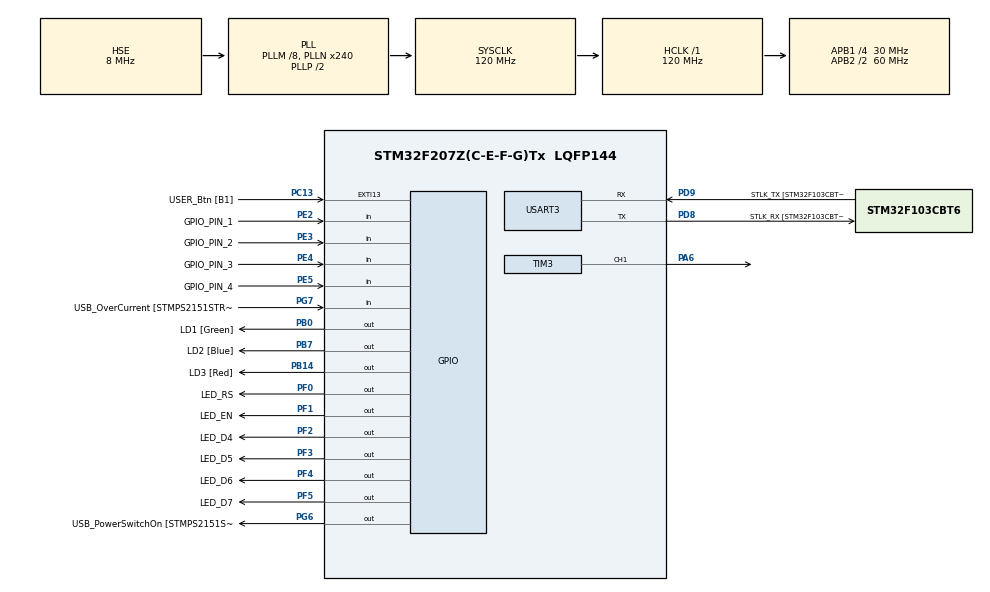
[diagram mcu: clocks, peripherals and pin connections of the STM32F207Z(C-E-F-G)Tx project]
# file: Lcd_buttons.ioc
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Mcu.Family=STM32F2
Mcu.Name=STM32F207Z(C-E-F-G)Tx
Mcu.Package=LQFP144
NVIC.PriorityGroup=NVIC_PRIORITYGROUP_4
NVIC.TIM3_IRQn=true\:0\:0\:false\:false\:true\:true\:true\:true
NVIC.TIM6_DAC_IRQn=true\:0\:0\:false\:false\:true\:true\:true\:true
PA1.GPIO_Label=RMII_REF_CLK [LAN8742A-CZ-TR_REFCLK0]
PA1.Signal=ETH_REF_CLK
PA10.GPIO_Label=USB_ID
PA10.Signal=USB_OTG_FS_ID
PA11.GPIO_Label=USB_DM
PA11.Signal=USB_OTG_FS_DM
PA12.GPIO_Label=USB_DP
PA12.Signal=USB_OTG_FS_DP
PA13.GPIO_Label=TMS
PA13.Mode=Serial_Wire
PA13.Signal=SYS_JTMS-SWDIO
PA14.GPIO_Label=TCK
PA14.Mode=Serial_Wire
PA14.Signal=SYS_JTCK-SWCLK
PA2.GPIO_Label=RMII_MDIO [LAN8742A-CZ-TR_MDIO]
PA2.Signal=ETH_MDIO
PA6.Signal=S_TIM3_CH1
PA7.GPIO_Label=RMII_CRS_DV [LAN8742A-CZ-TR_CRS_DV]
PA7.Signal=ETH_CRS_DV
PA8.GPIO_Label=USB_SOF [TP1]
PA8.Signal=USB_OTG_FS_SOF
PA9.GPIO_Label=USB_VBUS
PA9.Signal=USB_OTG_FS_VBUS
PB0.GPIO_Label=LD1 [Green]
PB0.Signal=GPIO_Output
PB13.GPIO_Label=RMII_TXD1 [LAN8742A-CZ-TR_TXD1]
PB13.Signal=ETH_TXD1
PB14.GPIO_Label=LD3 [Red]
PB14.Signal=GPIO_Output
PB3.GPIO_Label=SWO
PB3.Signal=SYS_JTDO-SWO
PB7.GPIO_Label=LD2 [Blue]
PB7.Signal=GPIO_Output
PC1.GPIO_Label=RMII_MDC [LAN8742A-CZ-TR_MDC]
PC1.Signal=ETH_MDC
PC13.GPIO_Label=USER_Btn [B1]
PC13.Signal=GPXTI13
PC14-OSC32_IN.Mode=LSE-External-Oscillator
PC14-OSC32_IN.Signal=RCC_OSC32_IN
PC15-OSC32_OUT.Mode=LSE-External-Oscillator
PC15-OSC32_OUT.Signal=RCC_OSC32_OUT
PC4.GPIO_Label=RMII_RXD0 [LAN8742A-CZ-TR_RXD0]
PC4.Signal=ETH_RXD0
PC5.GPIO_Label=RMII_RXD1 [LAN8742A-CZ-TR_RXD1]
PC5.Signal=ETH_RXD1
PD8.GPIO_Label=STLK_RX [STM32F103CBT6_PA2]
PD8.Mode=Asynchronous
PD8.Signal=USART3_TX
PD9.GPIO_Label=STLK_TX [STM32F103CBT6_PA3]
PD9.Mode=Asynchronous
PD9.Signal=USART3_RX
PE2.GPIO_Label=GPIO_PIN_1
PE2.GPIO_PuPd=GPIO_PULLDOWN
PE2.Signal=GPIO_Input
PE3.GPIO_Label=GPIO_PIN_2
PE3.GPIO_PuPd=GPIO_PULLDOWN
PE3.Signal=GPIO_Input
PE4.GPIO_Label=GPIO_PIN_3
PE4.GPIO_PuPd=GPIO_PULLDOWN
PE4.Signal=GPIO_Input
PE5.GPIO_Label=GPIO_PIN_4
PE5.GPIO_PuPd=GPIO_PULLDOWN
PE5.Signal=GPIO_Input
PF0.GPIO_Label=LED_RS
PF0.Signal=GPIO_Output
PF1.GPIO_Label=LED_EN
PF1.Signal=GPIO_Output
PF2.GPIO_Label=LED_D4
PF2.Signal=GPIO_Output
PF3.GPIO_Label=LED_D5
PF3.Signal=GPIO_Output
PF4.GPIO_Label=LED_D6
PF4.Signal=GPIO_Output
PF5.GPIO_Label=LED_D7
PF5.Signal=GPIO_Output
PG11.GPIO_Label=RMII_TX_EN [LAN8742A-CZ-TR_TXEN]
PG11.Signal=ETH_TX_EN
PG13.GPIO_Label=RMII_TXD0 [LAN8742A-CZ-TR_TXD0]
PG13.Signal=ETH_TXD0
PG6.GPIO_Label=USB_PowerSwitchOn [STMPS2151STR_EN]
PG6.Signal=GPIO_Output
PG7.GPIO_Label=USB_OverCurrent [STMPS2151STR_FAULT]
PG7.Signal=GPIO_Input
PH0-OSC_IN.GPIO_Label=MCO [STM32F103CBT6_PA8]
PH0-OSC_IN.Mode=HSE-External-Oscillator
PH0-OSC_IN.Signal=RCC_OSC_IN
PH1-OSC_OUT.Mode=HSE-External-Oscillator
PH1-OSC_OUT.Signal=RCC_OSC_OUT
ProjectManager.HeapSize=0x200
ProjectManager.StackSize=0x400
ProjectManager.TargetToolchain=STM32CubeIDE
RCC.48MHZClocksFreq_Value=48000000
RCC.AHBFreq_Value=120000000
RCC.APB1CLKDivider=RCC_HCLK_DIV4
RCC.APB1Freq_Value=30000000
RCC.APB1TimFreq_Value=60000000
RCC.APB2CLKDivider=RCC_HCLK_DIV2
RCC.APB2Freq_Value=60000000
RCC.APB2TimFreq_Value=120000000
RCC.CortexFreq_Value=120000000
RCC.HCLKFreq_Value=120000000
RCC.HSE_VALUE=8000000
RCC.HSI_VALUE=16000000
RCC.PLLM=8
RCC.PLLMUL=RCC_PLL_MUL9
RCC.PLLN=240
RCC.PLLQ=5
RCC.PLLSourceVirtual=RCC_PLLSOURCE_HSE
RCC.PRESCALERUSB=RCC_USBCLKSOURCE_PLL_DIV1_5
RCC.SYSCLKFreq_VALUE=120000000
RCC.SYSCLKSource=RCC_SYSCLKSOURCE_PLLCLK
RCC.SYSCLKSourceVirtual=RCC_SYSCLKSOURCE_PLLCLK
RCC.USBFreq_Value=48000000
RCC.VCOOutputFreq_Value=240000000
SH.S_TIM3_CH1.0=TIM3_CH1,PWM Generation1 CH1
TIM3.AutoReloadPreload=TIM_AUTORELOAD_PRELOAD_ENABLE
TIM3.Channel-PWM\ Generation1\ CH1=TIM_CHANNEL_1
TIM3.Period=100-1
TIM3.Prescaler=60000-1
TIM6.AutoReloadPreload=TIM_AUTORELOAD_PRELOAD_ENABLE
TIM6.Period=10-1
TIM6.Prescaler=60000-1
USART3.VirtualMode=VM_ASYNC
VP_TIM3_VS_ClockSourceINT.Mode=Internal
VP_TIM6_VS_ClockSourceINT.Mode=Enable_Timer
board=NUCLEO-F207ZG

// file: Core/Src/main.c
/* USER CODE BEGIN Header */
/**
  ******************************************************************************
  * @file           : main.c
  * @brief          : Main program body
  ******************************************************************************
  * @attention
  *
  * Copyright (c) 2024 STMicroelectronics.
  * All rights reserved.
  *
  * This software is licensed under terms that can be found in the LICENSE file
  * in the root directory of this software component.
  * If no LICENSE file comes with this software, it is provided AS-IS.
  *
  ******************************************************************************
  */
/* USER CODE END Header */
#include "main.h"
#include "button.h"

TIM_HandleTypeDef htim3;
TIM_HandleTypeDef htim6;

UART_HandleTypeDef huart3;

void SystemClock_Config(void);
static void MX_GPIO_Init(void);
static void MX_USART3_UART_Init(void);
static void MX_TIM3_Init(void);
static void MX_TIM6_Init(void);
/* USER CODE BEGIN PFP */
void checkButtonPress(void);
uint8_t counter1;
uint8_t counter2;
/* USER CODE END PFP */

/* USER CODE BEGIN 0 */
uint8_t GetGpio(uint16_t gpio) {
    // Assuming all buttons are on GPIOA; adjust as necessary
    return HAL_GPIO_ReadPin(GPIOE, gpio); // Adjust GPIO port as necessary
}
/* USER CODE END 0 */

int main(void)
{

  /* MCU Configuration--------------------------------------------------------*/

  /* Reset of all peripherals, Initializes the Flash interface and the Systick. */
  HAL_Init();

  /* Configure the system clock */
  SystemClock_Config();

  /* Initialize all configured peripherals */
  MX_GPIO_Init();
  MX_USART3_UART_Init();
  MX_TIM3_Init();
  MX_TIM6_Init();
  /* USER CODE BEGIN 2 */
  HAL_TIM_PWM_Start(&htim3, TIM_CHANNEL_1);
  HAL_TIM_Base_Start_IT(&htim6);

  /* USER CODE END 2 */

  /* Infinite loop */
  while (1)
  {

  }
}
void send_to_lcd (char data, int rs)
{
	HAL_GPIO_WritePin(LED_RS_GPIO_Port, LED_RS_Pin, rs);  // rs = 1 for data, rs=0 for command

	/* write the data to the respective pin */
	HAL_GPIO_WritePin(LED_D7_GPIO_Port, LED_D7_Pin, ((data>>3)&0x01));
	HAL_GPIO_WritePin(LED_D6_GPIO_Port, LED_D6_Pin, ((data>>2)&0x01));
	HAL_GPIO_WritePin(LED_D5_GPIO_Port, LED_D5_Pin, ((data>>1)&0x01));
	HAL_GPIO_WritePin(LED_D4_GPIO_Port, LED_D4_Pin, ((data>>0)&0x01));

	/* Toggle EN PIN to send the data
	 * if the HCLK > 100 MHz, use the  20 us delay
	 * if the LCD still doesn't work, increase the delay to 50, 80 or 100..
	 */
	HAL_GPIO_WritePin(LED_EN_GPIO_Port, LED_EN_Pin, 1);
	HAL_Delay (20);
	HAL_GPIO_WritePin(LED_EN_GPIO_Port, LED_EN_Pin, 0);
	HAL_Delay (20);
}
void HAL_TIM_PeriodElapsedCallback(TIM_HandleTypeDef *htim) {
    if (htim->Instance == TIM6)
    {
    	ButtonStatus(&Buttons[UP_BUTTON]);
    	if (Buttons[UP_BUTTON].gpio_state == High)
    	{
    		main_display(UP_BUTTON);
    	}
    	ButtonStatus(&Buttons[DOWN_BUTTON]);
    	if (Buttons[DOWN_BUTTON].gpio_state == High)
    	{
    		main_display(DOWN_BUTTON);
    	}
    	ButtonStatus(&Buttons[ENTER_BUTTON]);
    	if (Buttons[ENTER_BUTTON].gpio_state == High)
    	{
    		main_display(ENTER_BUTTON);
    	}
    	ButtonStatus(&Buttons[BACK_BUTTON]);
    	if (Buttons[BACK_BUTTON].gpio_state == High)
    	{
    		main_display(BACK_BUTTON);
    	}
    }

}
void SystemClock_Config(void)
{
  RCC_OscInitTypeDef RCC_OscInitStruct = {0};
  RCC_ClkInitTypeDef RCC_ClkInitStruct = {0};

  /** Initializes the RCC Oscillators according to the specified parameters
  * in the RCC_OscInitTypeDef structure.
  */
  RCC_OscInitStruct.OscillatorType = RCC_OSCILLATORTYPE_HSE;
  RCC_OscInitStruct.HSEState = RCC_HSE_ON;
  RCC_OscInitStruct.PLL.PLLState = RCC_PLL_ON;
  RCC_OscInitStruct.PLL.PLLSource = RCC_PLLSOURCE_HSE;
  RCC_OscInitStruct.PLL.PLLM = 8;
  RCC_OscInitStruct.PLL.PLLN = 240;
  RCC_OscInitStruct.PLL.PLLP = RCC_PLLP_DIV2;
  RCC_OscInitStruct.PLL.PLLQ = 5;
  if (HAL_RCC_OscConfig(&RCC_OscInitStruct) != HAL_OK)
  {
    Error_Handler();
  }

  /** Initializes the CPU, AHB and APB buses clocks
  */
  RCC_ClkInitStruct.ClockType = RCC_CLOCKTYPE_HCLK|RCC_CLOCKTYPE_SYSCLK
                              |RCC_CLOCKTYPE_PCLK1|RCC_CLOCKTYPE_PCLK2;
  RCC_ClkInitStruct.SYSCLKSource = RCC_SYSCLKSOURCE_PLLCLK;
  RCC_ClkInitStruct.AHBCLKDivider = RCC_SYSCLK_DIV1;
  RCC_ClkInitStruct.APB1CLKDivider = RCC_HCLK_DIV4;
  RCC_ClkInitStruct.APB2CLKDivider = RCC_HCLK_DIV2;

  if (HAL_RCC_ClockConfig(&RCC_ClkInitStruct, FLASH_LATENCY_3) != HAL_OK)
  {
    Error_Handler();
  }
}

static void MX_TIM3_Init(void)
{

  TIM_ClockConfigTypeDef sClockSourceConfig = {0};
  TIM_MasterConfigTypeDef sMasterConfig = {0};
  TIM_OC_InitTypeDef sConfigOC = {0};

  htim3.Instance = TIM3;
  htim3.Init.Prescaler = 60000-1;
  htim3.Init.CounterMode = TIM_COUNTERMODE_UP;
  htim3.Init.Period = 100-1;
  htim3.Init.ClockDivision = TIM_CLOCKDIVISION_DIV1;
  htim3.Init.AutoReloadPreload = TIM_AUTORELOAD_PRELOAD_ENABLE;
  if (HAL_TIM_Base_Init(&htim3) != HAL_OK)
  {
    Error_Handler();
  }
  sClockSourceConfig.ClockSource = TIM_CLOCKSOURCE_INTERNAL;
  if (HAL_TIM_ConfigClockSource(&htim3, &sClockSourceConfig) != HAL_OK)
  {
    Error_Handler();
  }
  if (HAL_TIM_PWM_Init(&htim3) != HAL_OK)
  {
    Error_Handler();
  }
  sMasterConfig.MasterOutputTrigger = TIM_TRGO_RESET;
  sMasterConfig.MasterSlaveMode = TIM_MASTERSLAVEMODE_DISABLE;
  if (HAL_TIMEx_MasterConfigSynchronization(&htim3, &sMasterConfig) != HAL_OK)
  {
    Error_Handler();
  }
  sConfigOC.OCMode = TIM_OCMODE_PWM1;
  sConfigOC.Pulse = 52;
  sConfigOC.OCPolarity = TIM_OCPOLARITY_HIGH;
  sConfigOC.OCFastMode = TIM_OCFAST_DISABLE;
  if (HAL_TIM_PWM_ConfigChannel(&htim3, &sConfigOC, TIM_CHANNEL_1) != HAL_OK)
  {
    Error_Handler();
  }
  HAL_TIM_MspPostInit(&htim3);

}

static void MX_TIM6_Init(void)
{

  TIM_MasterConfigTypeDef sMasterConfig = {0};

  htim6.Instance = TIM6;
  htim6.Init.Prescaler = 60000-1;
  htim6.Init.CounterMode = TIM_COUNTERMODE_UP;
  htim6.Init.Period = 10-1;
  htim6.Init.AutoReloadPreload = TIM_AUTORELOAD_PRELOAD_ENABLE;
  if (HAL_TIM_Base_Init(&htim6) != HAL_OK)
  {
    Error_Handler();
  }
  sMasterConfig.MasterOutputTrigger = TIM_TRGO_RESET;
  sMasterConfig.MasterSlaveMode = TIM_MASTERSLAVEMODE_DISABLE;
  if (HAL_TIMEx_MasterConfigSynchronization(&htim6, &sMasterConfig) != HAL_OK)
  {
    Error_Handler();
  }

}

static void MX_USART3_UART_Init(void)
{

  huart3.Instance = USART3;
  huart3.Init.BaudRate = 115200;
  huart3.Init.WordLength = UART_WORDLENGTH_8B;
  huart3.Init.StopBits = UART_STOPBITS_1;
  huart3.Init.Parity = UART_PARITY_NONE;
  huart3.Init.Mode = UART_MODE_TX_RX;
  huart3.Init.HwFlowCtl = UART_HWCONTROL_NONE;
  huart3.Init.OverSampling = UART_OVERSAMPLING_16;
  if (HAL_UART_Init(&huart3) != HAL_OK)
  {
    Error_Handler();
  }

}

static void MX_GPIO_Init(void)
{
  GPIO_InitTypeDef GPIO_InitStruct = {0};

  /* GPIO Ports Clock Enable */
  __HAL_RCC_GPIOE_CLK_ENABLE();
  __HAL_RCC_GPIOC_CLK_ENABLE();
  __HAL_RCC_GPIOF_CLK_ENABLE();
  __HAL_RCC_GPIOH_CLK_ENABLE();
  __HAL_RCC_GPIOA_CLK_ENABLE();
  __HAL_RCC_GPIOB_CLK_ENABLE();
  __HAL_RCC_GPIOD_CLK_ENABLE();
  __HAL_RCC_GPIOG_CLK_ENABLE();

  /*Configure GPIO pin Output Level */
  HAL_GPIO_WritePin(GPIOF, LED_RS_Pin|LED_EN_Pin|LED_D4_Pin|LED_D5_Pin
                          |LED_D6_Pin|LED_D7_Pin, GPIO_PIN_RESET);

  /*Configure GPIO pin Output Level */
  HAL_GPIO_WritePin(GPIOB, LD1_Pin|LD3_Pin|LD2_Pin, GPIO_PIN_RESET);

  /*Configure GPIO pin Output Level */
  HAL_GPIO_WritePin(USB_PowerSwitchOn_GPIO_Port, USB_PowerSwitchOn_Pin, GPIO_PIN_RESET);

  /*Configure GPIO pins : PEPin PEPin PEPin PEPin */
  GPIO_InitStruct.Pin = GPIO_PIN_1_Pin|GPIO_PIN_2_Pin|GPIO_PIN_3_Pin|GPIO_PIN_4_Pin;
  GPIO_InitStruct.Mode = GPIO_MODE_INPUT;
  GPIO_InitStruct.Pull = GPIO_PULLDOWN;
  HAL_GPIO_Init(GPIOE, &GPIO_InitStruct);

  /*Configure GPIO pin : USER_Btn_Pin */
  GPIO_InitStruct.Pin = USER_Btn_Pin;
  GPIO_InitStruct.Mode = GPIO_MODE_IT_RISING;
  GPIO_InitStruct.Pull = GPIO_NOPULL;
  HAL_GPIO_Init(USER_Btn_GPIO_Port, &GPIO_InitStruct);

  /*Configure GPIO pins : LED_RS_Pin LED_EN_Pin LED_D4_Pin LED_D5_Pin
                           LED_D6_Pin LED_D7_Pin */
  GPIO_InitStruct.Pin = LED_RS_Pin|LED_EN_Pin|LED_D4_Pin|LED_D5_Pin
                          |LED_D6_Pin|LED_D7_Pin;
  GPIO_InitStruct.Mode = GPIO_MODE_OUTPUT_PP;
  GPIO_InitStruct.Pull = GPIO_NOPULL;
  GPIO_InitStruct.Speed = GPIO_SPEED_FREQ_LOW;
  HAL_GPIO_Init(GPIOF, &GPIO_InitStruct);

  /*Configure GPIO pins : RMII_MDC_Pin RMII_RXD0_Pin RMII_RXD1_Pin */
  GPIO_InitStruct.Pin = RMII_MDC_Pin|RMII_RXD0_Pin|RMII_RXD1_Pin;
  GPIO_InitStruct.Mode = GPIO_MODE_AF_PP;
  GPIO_InitStruct.Pull = GPIO_NOPULL;
  GPIO_InitStruct.Speed = GPIO_SPEED_FREQ_VERY_HIGH;
  GPIO_InitStruct.Alternate = GPIO_AF11_ETH;
  HAL_GPIO_Init(GPIOC, &GPIO_InitStruct);

  /*Configure GPIO pins : RMII_REF_CLK_Pin RMII_MDIO_Pin RMII_CRS_DV_Pin */
  GPIO_InitStruct.Pin = RMII_REF_CLK_Pin|RMII_MDIO_Pin|RMII_CRS_DV_Pin;
  GPIO_InitStruct.Mode = GPIO_MODE_AF_PP;
  GPIO_InitStruct.Pull = GPIO_NOPULL;
  GPIO_InitStruct.Speed = GPIO_SPEED_FREQ_VERY_HIGH;
  GPIO_InitStruct.Alternate = GPIO_AF11_ETH;
  HAL_GPIO_Init(GPIOA, &GPIO_InitStruct);

  /*Configure GPIO pins : LD1_Pin LD3_Pin LD2_Pin */
  GPIO_InitStruct.Pin = LD1_Pin|LD3_Pin|LD2_Pin;
  GPIO_InitStruct.Mode = GPIO_MODE_OUTPUT_PP;
  GPIO_InitStruct.Pull = GPIO_NOPULL;
  GPIO_InitStruct.Speed = GPIO_SPEED_FREQ_LOW;
  HAL_GPIO_Init(GPIOB, &GPIO_InitStruct);

  /*Configure GPIO pin : RMII_TXD1_Pin */
  GPIO_InitStruct.Pin = RMII_TXD1_Pin;
  GPIO_InitStruct.Mode = GPIO_MODE_AF_PP;
  GPIO_InitStruct.Pull = GPIO_NOPULL;
  GPIO_InitStruct.Speed = GPIO_SPEED_FREQ_VERY_HIGH;
  GPIO_InitStruct.Alternate = GPIO_AF11_ETH;
  HAL_GPIO_Init(RMII_TXD1_GPIO_Port, &GPIO_InitStruct);

  /*Configure GPIO pin : USB_PowerSwitchOn_Pin */
  GPIO_InitStruct.Pin = USB_PowerSwitchOn_Pin;
  GPIO_InitStruct.Mode = GPIO_MODE_OUTPUT_PP;
  GPIO_InitStruct.Pull = GPIO_NOPULL;
  GPIO_InitStruct.Speed = GPIO_SPEED_FREQ_LOW;
  HAL_GPIO_Init(USB_PowerSwitchOn_GPIO_Port, &GPIO_InitStruct);

  /*Configure GPIO pin : USB_OverCurrent_Pin */
  GPIO_InitStruct.Pin = USB_OverCurrent_Pin;
  GPIO_InitStruct.Mode = GPIO_MODE_INPUT;
  GPIO_InitStruct.Pull = GPIO_NOPULL;
  HAL_GPIO_Init(USB_OverCurrent_GPIO_Port, &GPIO_InitStruct);

  /*Configure GPIO pins : USB_SOF_Pin USB_ID_Pin USB_DM_Pin USB_DP_Pin */
  GPIO_InitStruct.Pin = USB_SOF_Pin|USB_ID_Pin|USB_DM_Pin|USB_DP_Pin;
  GPIO_InitStruct.Mode = GPIO_MODE_AF_PP;
  GPIO_InitStruct.Pull = GPIO_NOPULL;
  GPIO_InitStruct.Speed = GPIO_SPEED_FREQ_VERY_HIGH;
  GPIO_InitStruct.Alternate = GPIO_AF10_OTG_FS;
  HAL_GPIO_Init(GPIOA, &GPIO_InitStruct);

  /*Configure GPIO pin : USB_VBUS_Pin */
  GPIO_InitStruct.Pin = USB_VBUS_Pin;
  GPIO_InitStruct.Mode = GPIO_MODE_INPUT;
  GPIO_InitStruct.Pull = GPIO_NOPULL;
  HAL_GPIO_Init(USB_VBUS_GPIO_Port, &GPIO_InitStruct);

  /*Configure GPIO pins : RMII_TX_EN_Pin RMII_TXD0_Pin */
  GPIO_InitStruct.Pin = RMII_TX_EN_Pin|RMII_TXD0_Pin;
  GPIO_InitStruct.Mode = GPIO_MODE_AF_PP;
  GPIO_InitStruct.Pull = GPIO_NOPULL;
  GPIO_InitStruct.Speed = GPIO_SPEED_FREQ_VERY_HIGH;
  GPIO_InitStruct.Alternate = GPIO_AF11_ETH;
  HAL_GPIO_Init(GPIOG, &GPIO_InitStruct);

}

void Error_Handler(void)
{
  __disable_irq();
  while (1)
  {
  }
}
